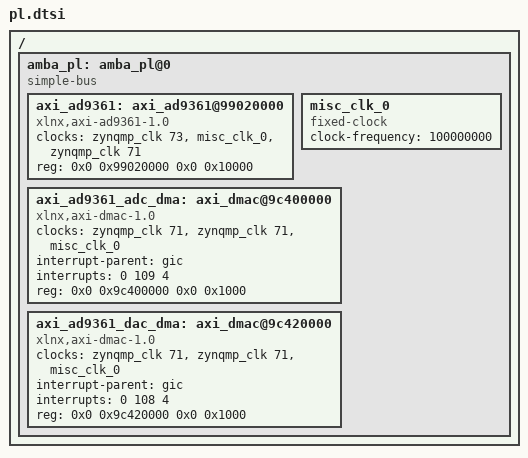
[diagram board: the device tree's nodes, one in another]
/*
 * CAUTION: This file is automatically generated by Xilinx.
 * Version:  
 * Today is: Sat Sep  2 12:16:36 2023
 */


/ {
	amba_pl: amba_pl@0 {
		#address-cells = <2>;
		#size-cells = <2>;
		compatible = "simple-bus";
		ranges ;
		axi_ad9361: axi_ad9361@99020000 {
			clock-names = "delay_clk", "clk", "s_axi_aclk";
			clocks = <&zynqmp_clk 73>, <&misc_clk_0>, <&zynqmp_clk 71>;
			compatible = "xlnx,axi-ad9361-1.0";
			reg = <0x0 0x99020000 0x0 0x10000>;
		};
		misc_clk_0: misc_clk_0 {
			#clock-cells = <0>;
			clock-frequency = <100000000>;
			compatible = "fixed-clock";
		};
		axi_ad9361_adc_dma: axi_dmac@9c400000 {
			clock-names = "s_axi_aclk", "m_dest_axi_aclk", "fifo_wr_clk";
			clocks = <&zynqmp_clk 71>, <&zynqmp_clk 71>, <&misc_clk_0>;
			compatible = "xlnx,axi-dmac-1.0";
			interrupt-names = "irq";
			interrupt-parent = <&gic>;
			interrupts = <0 109 4>;
			reg = <0x0 0x9c400000 0x0 0x1000>;
		};
		axi_ad9361_dac_dma: axi_dmac@9c420000 {
			clock-names = "s_axi_aclk", "m_src_axi_aclk", "m_axis_aclk";
			clocks = <&zynqmp_clk 71>, <&zynqmp_clk 71>, <&misc_clk_0>;
			compatible = "xlnx,axi-dmac-1.0";
			interrupt-names = "irq";
			interrupt-parent = <&gic>;
			interrupts = <0 108 4>;
			reg = <0x0 0x9c420000 0x0 0x1000>;
		};
	};
};
